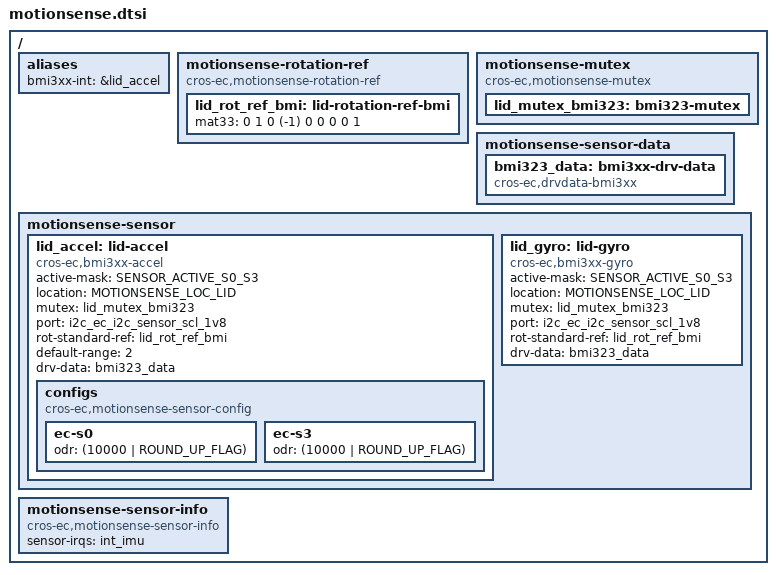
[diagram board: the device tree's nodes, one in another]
/* Copyright 2025 The ChromiumOS Authors
 * Use of this source code is governed by a BSD-style license that can be
 * found in the LICENSE file.
 */

#include <dt-bindings/motionsense/utils.h>

/ {
	aliases {
		bmi3xx-int = &lid_accel;
	};

	/* Rotation matrix used by drivers. */
	motionsense-rotation-ref {
		compatible = "cros-ec,motionsense-rotation-ref";
		lid_rot_ref_bmi: lid-rotation-ref-bmi {
			mat33 = <0 1 0
				 (-1) 0 0
				 0 0 1>;
		};
	};

	/*
	 * Declare mutexes used by sensor drivers.
	 * A mutex node is used to create an instance of mutex_t.
	 * A mutex node is referenced by a sensor node if the
	 * corresponding sensor driver needs to use the
	 * instance of the mutex.
	 */

	motionsense-mutex {
		compatible = "cros-ec,motionsense-mutex";
		lid_mutex_bmi323: bmi323-mutex {
		};
	};

	/* Driver specific data */
	motionsense-sensor-data {
		bmi323_data: bmi3xx-drv-data {
			compatible = "cros-ec,drvdata-bmi3xx";
			status = "okay";
		};
	};

	/* List of motion sensors that create motion_sensors array. */
	motionsense-sensor {
		lid_accel: lid-accel {
			compatible = "cros-ec,bmi3xx-accel";
			status = "okay";

			active-mask = "SENSOR_ACTIVE_S0_S3";
			location = "MOTIONSENSE_LOC_LID";
			mutex = <&lid_mutex_bmi323>;
			port = <&i2c_ec_i2c_sensor_scl_1v8>;
			rot-standard-ref = <&lid_rot_ref_bmi>;
			default-range = <2>;
			drv-data = <&bmi323_data>;
			configs {
				compatible =
					"cros-ec,motionsense-sensor-config";
				ec-s0 {
					odr = <(10000 | ROUND_UP_FLAG)>;
				};
				ec-s3 {
					odr = <(10000 | ROUND_UP_FLAG)>;
				};
			};
		};

		lid_gyro: lid-gyro {
			compatible = "cros-ec,bmi3xx-gyro";
			status = "okay";

			active-mask = "SENSOR_ACTIVE_S0_S3";
			location = "MOTIONSENSE_LOC_LID";
			mutex = <&lid_mutex_bmi323>;
			port = <&i2c_ec_i2c_sensor_scl_1v8>;
			rot-standard-ref = <&lid_rot_ref_bmi>;
			drv-data = <&bmi323_data>;
		};
	};

	/* High level description info */
	motionsense-sensor-info {
		compatible = "cros-ec,motionsense-sensor-info";
		/*
		 * List of GPIO interrupts that have to be enabled at initial
		 * stage.
		 */
		sensor-irqs = <&int_imu>;
	};
};
